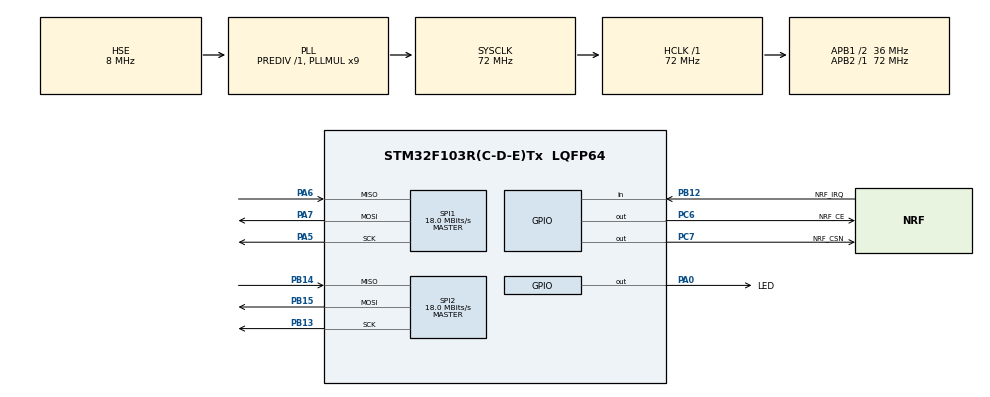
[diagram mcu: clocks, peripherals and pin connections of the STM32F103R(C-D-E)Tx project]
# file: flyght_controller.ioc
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FREERTOS.BinarySemaphores01=myBinarySem01,Dynamic,NULL
FREERTOS.Events01=myEvent01,Dynamic,NULL
FREERTOS.Mutexes01=myMutex01,Dynamic,NULL
FREERTOS.Queues01=myQueue01,16,uint16_t,0,Dynamic,NULL,NULL
FREERTOS.Tasks01=defaultTask,24,128,StartDefaultTask,Default,NULL,Dynamic,NULL,NULL;blinker,8,128,startBlink,Default,NULL,Dynamic,NULL,NULL
FREERTOS.configUSE_NEWLIB_REENTRANT=1
Mcu.Family=STM32F1
Mcu.Name=STM32F103R(C-D-E)Tx
Mcu.Package=LQFP64
NVIC.PriorityGroup=NVIC_PRIORITYGROUP_4
PA0-WKUP.GPIO_Label=LED
PA0-WKUP.Signal=GPIO_Output
PA13.Mode=Serial_Wire
PA13.Signal=SYS_JTMS-SWDIO
PA14.Mode=Serial_Wire
PA14.Signal=SYS_JTCK-SWCLK
PA5.Mode=Full_Duplex_Master
PA5.Signal=SPI1_SCK
PA6.Mode=Full_Duplex_Master
PA6.Signal=SPI1_MISO
PA7.Mode=Full_Duplex_Master
PA7.Signal=SPI1_MOSI
PB12.GPIO_Label=NRF_IRQ
PB12.Signal=GPIO_Input
PB13.Mode=Full_Duplex_Master
PB13.Signal=SPI2_SCK
PB14.Mode=Full_Duplex_Master
PB14.Signal=SPI2_MISO
PB15.Mode=Full_Duplex_Master
PB15.Signal=SPI2_MOSI
PC6.GPIO_Label=NRF_CE
PC6.Signal=GPIO_Output
PC7.GPIO_Label=NRF_CSN
PC7.Signal=GPIO_Output
PD0-OSC_IN.Mode=HSE-External-Oscillator
PD0-OSC_IN.Signal=RCC_OSC_IN
PD1-OSC_OUT.Mode=HSE-External-Oscillator
PD1-OSC_OUT.Signal=RCC_OSC_OUT
ProjectManager.HeapSize=0x200
ProjectManager.StackSize=0x400
ProjectManager.TargetToolchain=STM32CubeIDE
RCC.AHBFreq_Value=72000000
RCC.APB1CLKDivider=RCC_HCLK_DIV2
RCC.APB1Freq_Value=36000000
RCC.APB1TimFreq_Value=72000000
RCC.APB2Freq_Value=72000000
RCC.APB2TimFreq_Value=72000000
RCC.HCLKFreq_Value=72000000
RCC.PLLMUL=RCC_PLL_MUL9
RCC.PLLSourceVirtual=RCC_PLLSOURCE_HSE
RCC.SYSCLKFreq_VALUE=72000000
RCC.SYSCLKSource=RCC_SYSCLKSOURCE_PLLCLK
RCC.USBFreq_Value=48000000
RCC.USBPrescaler=RCC_USBCLKSOURCE_PLL_DIV1_5
SPI1.BaudRatePrescaler=SPI_BAUDRATEPRESCALER_4
SPI1.CalculateBaudRate=18.0 MBits/s
SPI1.Direction=SPI_DIRECTION_2LINES
SPI1.Mode=SPI_MODE_MASTER
SPI1.VirtualType=VM_MASTER
SPI2.BaudRatePrescaler=SPI_BAUDRATEPRESCALER_2
SPI2.CalculateBaudRate=18.0 MBits/s
SPI2.Direction=SPI_DIRECTION_2LINES
SPI2.Mode=SPI_MODE_MASTER
SPI2.VirtualType=VM_MASTER
VP_FREERTOS_VS_CMSIS_V2.Mode=CMSIS_V2
board=custom

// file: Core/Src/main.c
/* USER CODE BEGIN Header */
/**
  ******************************************************************************
  * @file           : main.c
  * @brief          : Main program body
  ******************************************************************************
  * @attention
  *
  * Copyright (c) 2022 STMicroelectronics.
  * All rights reserved.
  *
  * This software is licensed under terms that can be found in the LICENSE file
  * in the root directory of this software component.
  * If no LICENSE file comes with this software, it is provided AS-IS.
  *
  ******************************************************************************
  */
/* USER CODE END Header */
#include "main.h"
#include "cmsis_os.h"

SPI_HandleTypeDef hspi1;
SPI_HandleTypeDef hspi2;

/* Definitions for defaultTask */
osThreadId_t defaultTaskHandle;
const osThreadAttr_t defaultTask_attributes = {
  .name = "defaultTask",
  .stack_size = 128 * 4,
  .priority = (osPriority_t) osPriorityNormal,
};
/* Definitions for blinker */
osThreadId_t blinkerHandle;
const osThreadAttr_t blinker_attributes = {
  .name = "blinker",
  .stack_size = 128 * 4,
  .priority = (osPriority_t) osPriorityLow,
};
/* Definitions for myQueue01 */
osMessageQueueId_t myQueue01Handle;
const osMessageQueueAttr_t myQueue01_attributes = {
  .name = "myQueue01"
};
/* Definitions for myMutex01 */
osMutexId_t myMutex01Handle;
const osMutexAttr_t myMutex01_attributes = {
  .name = "myMutex01"
};
/* Definitions for myBinarySem01 */
osSemaphoreId_t myBinarySem01Handle;
const osSemaphoreAttr_t myBinarySem01_attributes = {
  .name = "myBinarySem01"
};
/* Definitions for myEvent01 */
osEventFlagsId_t myEvent01Handle;
const osEventFlagsAttr_t myEvent01_attributes = {
  .name = "myEvent01"
};

void SystemClock_Config(void);
static void MX_GPIO_Init(void);
static void MX_SPI1_Init(void);
static void MX_SPI2_Init(void);
void StartDefaultTask(void *argument);
void startBlink(void *argument);

int main(void)
{

  /* MCU Configuration--------------------------------------------------------*/

  /* Reset of all peripherals, Initializes the Flash interface and the Systick. */
  HAL_Init();

  /* Configure the system clock */
  SystemClock_Config();

  /* Initialize all configured peripherals */
  MX_GPIO_Init();
  MX_SPI1_Init();
  MX_SPI2_Init();
  /* USER CODE BEGIN 2 */
  HAL_GPIO_TogglePin(LED_GPIO_Port, LED_Pin);
  /* USER CODE END 2 */

  /* Init scheduler */
  osKernelInitialize();
  /* Create the mutex(es) */
  /* creation of myMutex01 */
  myMutex01Handle = osMutexNew(&myMutex01_attributes);

  /* Create the semaphores(s) */
  /* creation of myBinarySem01 */
  myBinarySem01Handle = osSemaphoreNew(1, 1, &myBinarySem01_attributes);

  /* Create the queue(s) */
  /* creation of myQueue01 */
  myQueue01Handle = osMessageQueueNew (16, sizeof(uint16_t), &myQueue01_attributes);

  /* Create the thread(s) */
  /* creation of defaultTask */
  defaultTaskHandle = osThreadNew(StartDefaultTask, NULL, &defaultTask_attributes);

  /* creation of blinker */
  blinkerHandle = osThreadNew(startBlink, NULL, &blinker_attributes);

  /* creation of myEvent01 */
  myEvent01Handle = osEventFlagsNew(&myEvent01_attributes);

  /* Start scheduler */
  osKernelStart();

  /* We should never get here as control is now taken by the scheduler */
  /* Infinite loop */
  while (1)
  {

  }
}

void SystemClock_Config(void)
{
  RCC_OscInitTypeDef RCC_OscInitStruct = {0};
  RCC_ClkInitTypeDef RCC_ClkInitStruct = {0};

  /** Initializes the RCC Oscillators according to the specified parameters
  * in the RCC_OscInitTypeDef structure.
  */
  RCC_OscInitStruct.OscillatorType = RCC_OSCILLATORTYPE_HSE;
  RCC_OscInitStruct.HSEState = RCC_HSE_ON;
  RCC_OscInitStruct.HSEPredivValue = RCC_HSE_PREDIV_DIV1;
  RCC_OscInitStruct.HSIState = RCC_HSI_ON;
  RCC_OscInitStruct.PLL.PLLState = RCC_PLL_ON;
  RCC_OscInitStruct.PLL.PLLSource = RCC_PLLSOURCE_HSE;
  RCC_OscInitStruct.PLL.PLLMUL = RCC_PLL_MUL9;
  if (HAL_RCC_OscConfig(&RCC_OscInitStruct) != HAL_OK)
  {
    Error_Handler();
  }

  /** Initializes the CPU, AHB and APB buses clocks
  */
  RCC_ClkInitStruct.ClockType = RCC_CLOCKTYPE_HCLK|RCC_CLOCKTYPE_SYSCLK
                              |RCC_CLOCKTYPE_PCLK1|RCC_CLOCKTYPE_PCLK2;
  RCC_ClkInitStruct.SYSCLKSource = RCC_SYSCLKSOURCE_PLLCLK;
  RCC_ClkInitStruct.AHBCLKDivider = RCC_SYSCLK_DIV1;
  RCC_ClkInitStruct.APB1CLKDivider = RCC_HCLK_DIV2;
  RCC_ClkInitStruct.APB2CLKDivider = RCC_HCLK_DIV1;

  if (HAL_RCC_ClockConfig(&RCC_ClkInitStruct, FLASH_LATENCY_2) != HAL_OK)
  {
    Error_Handler();
  }
}

static void MX_SPI1_Init(void)
{

  /* SPI1 parameter configuration*/
  hspi1.Instance = SPI1;
  hspi1.Init.Mode = SPI_MODE_MASTER;
  hspi1.Init.Direction = SPI_DIRECTION_2LINES;
  hspi1.Init.DataSize = SPI_DATASIZE_8BIT;
  hspi1.Init.CLKPolarity = SPI_POLARITY_LOW;
  hspi1.Init.CLKPhase = SPI_PHASE_1EDGE;
  hspi1.Init.NSS = SPI_NSS_SOFT;
  hspi1.Init.BaudRatePrescaler = SPI_BAUDRATEPRESCALER_4;
  hspi1.Init.FirstBit = SPI_FIRSTBIT_MSB;
  hspi1.Init.TIMode = SPI_TIMODE_DISABLE;
  hspi1.Init.CRCCalculation = SPI_CRCCALCULATION_DISABLE;
  hspi1.Init.CRCPolynomial = 10;
  if (HAL_SPI_Init(&hspi1) != HAL_OK)
  {
    Error_Handler();
  }

}

static void MX_SPI2_Init(void)
{

  /* SPI2 parameter configuration*/
  hspi2.Instance = SPI2;
  hspi2.Init.Mode = SPI_MODE_MASTER;
  hspi2.Init.Direction = SPI_DIRECTION_2LINES;
  hspi2.Init.DataSize = SPI_DATASIZE_8BIT;
  hspi2.Init.CLKPolarity = SPI_POLARITY_LOW;
  hspi2.Init.CLKPhase = SPI_PHASE_1EDGE;
  hspi2.Init.NSS = SPI_NSS_SOFT;
  hspi2.Init.BaudRatePrescaler = SPI_BAUDRATEPRESCALER_2;
  hspi2.Init.FirstBit = SPI_FIRSTBIT_MSB;
  hspi2.Init.TIMode = SPI_TIMODE_DISABLE;
  hspi2.Init.CRCCalculation = SPI_CRCCALCULATION_DISABLE;
  hspi2.Init.CRCPolynomial = 10;
  if (HAL_SPI_Init(&hspi2) != HAL_OK)
  {
    Error_Handler();
  }

}

static void MX_GPIO_Init(void)
{
  GPIO_InitTypeDef GPIO_InitStruct = {0};

  /* GPIO Ports Clock Enable */
  __HAL_RCC_GPIOD_CLK_ENABLE();
  __HAL_RCC_GPIOA_CLK_ENABLE();
  __HAL_RCC_GPIOB_CLK_ENABLE();
  __HAL_RCC_GPIOC_CLK_ENABLE();

  /*Configure GPIO pin Output Level */
  HAL_GPIO_WritePin(LED_GPIO_Port, LED_Pin, GPIO_PIN_RESET);

  /*Configure GPIO pin Output Level */
  HAL_GPIO_WritePin(GPIOC, NRF_CE_Pin|NRF_CSN_Pin, GPIO_PIN_RESET);

  /*Configure GPIO pin : LED_Pin */
  GPIO_InitStruct.Pin = LED_Pin;
  GPIO_InitStruct.Mode = GPIO_MODE_OUTPUT_PP;
  GPIO_InitStruct.Pull = GPIO_NOPULL;
  GPIO_InitStruct.Speed = GPIO_SPEED_FREQ_LOW;
  HAL_GPIO_Init(LED_GPIO_Port, &GPIO_InitStruct);

  /*Configure GPIO pin : NRF_IRQ_Pin */
  GPIO_InitStruct.Pin = NRF_IRQ_Pin;
  GPIO_InitStruct.Mode = GPIO_MODE_INPUT;
  GPIO_InitStruct.Pull = GPIO_NOPULL;
  HAL_GPIO_Init(NRF_IRQ_GPIO_Port, &GPIO_InitStruct);

  /*Configure GPIO pins : NRF_CE_Pin NRF_CSN_Pin */
  GPIO_InitStruct.Pin = NRF_CE_Pin|NRF_CSN_Pin;
  GPIO_InitStruct.Mode = GPIO_MODE_OUTPUT_PP;
  GPIO_InitStruct.Pull = GPIO_NOPULL;
  GPIO_InitStruct.Speed = GPIO_SPEED_FREQ_LOW;
  HAL_GPIO_Init(GPIOC, &GPIO_InitStruct);

}

void StartDefaultTask(void *argument)
{
  for(;;)
  {
    osDelay(1);
  }
}

void startBlink(void *argument)
{
  /* USER CODE BEGIN startBlink */
  /* Infinite loop */
  for(;;)
  {
	HAL_GPIO_TogglePin(LED_GPIO_Port, LED_Pin);
    osDelay(1000);
  }
  /* USER CODE END startBlink */
}

void Error_Handler(void)
{
  __disable_irq();
  while (1)
  {
  }
}
